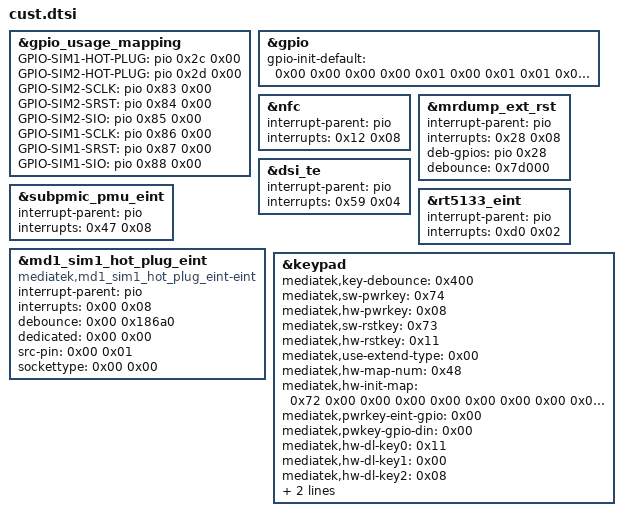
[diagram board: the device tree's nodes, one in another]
// SPDX-License-Identifier: (GPL-2.0 OR MIT)
/*
 * Reconstruction and modifications Copyright (C) 2026 YorokobiMaster (GitHub: @YorokobiMaster)
 *
 * Redmi Turbo 5 Max (dash) customer device-tree data reconstructed from
 * Xiaomi OS3.0.305.0.WPLCNXM stock dtbo.img.
 *
 * This reconstruction does not claim ownership of the original vendor
 * design, interfaces, hardware data, firmware, or other third-party
 * intellectual property. Such rights remain with their respective owners.
 */

&gpio_usage_mapping {
 GPIO-SIM1-HOT-PLUG = <&pio 0x2c 0x00>;
 GPIO-SIM2-HOT-PLUG = <&pio 0x2d 0x00>;
 GPIO-SIM2-SCLK = <&pio 0x83 0x00>;
 GPIO-SIM2-SRST = <&pio 0x84 0x00>;
 GPIO-SIM2-SIO = <&pio 0x85 0x00>;
 GPIO-SIM1-SCLK = <&pio 0x86 0x00>;
 GPIO-SIM1-SRST = <&pio 0x87 0x00>;
 GPIO-SIM1-SIO = <&pio 0x88 0x00>;
};

&gpio {
 gpio-init-default = < 0x00 0x00 0x00 0x00 0x01 0x00 0x01 0x01 0x00 0x01 0x00 0x01 0x00 0x01 0x02 0x00 0x00 0x00 0x01 0x00 0x01 0x03 0x00 0x01 0x00 0x01 0x00 0x01 0x04 0x01 0x00 0x00 0x01 0x00 0x01 0x05 0x00 0x00 0x00 0x01 0x00 0x01 0x06 0x00 0x00 0x00 0x01 0x00 0x01 0x07 0x00 0x00 0x00 0x01 0x01 0x01 0x08 0x00 0x01 0x00 0x01 0x00 0x01 0x09 0x00 0x01 0x01 0x01 0x00 0x01 0x0a 0x00 0x00 0x00 0x01 0x00 0x01 0x0b 0x00 0x00 0x00 0x01 0x00 0x01 0x0c 0x00 0x00 0x00 0x01 0x00 0x01 0x0d 0x00 0x01 0x00 0x01 0x00 0x01 0x0e 0x05 0x00 0x00 0x01 0x00 0x01 0x0f 0x01 0x00 0x00 0x01 0x00 0x01 0x10 0x00 0x00 0x00 0x01 0x00 0x01 0x11 0x00 0x00 0x00 0x01 0x00 0x01 0x12 0x00 0x00 0x00 0x01 0x01 0x01 0x13 0x00 0x01 0x00 0x01 0x00 0x01 0x14 0x00 0x00 0x00 0x01 0x00 0x01 0x15 0x01 0x00 0x00 0x00 0x00 0x01 0x16 0x01 0x00 0x00 0x00 0x00 0x01 0x17 0x01 0x00 0x00 0x00 0x00 0x01 0x18 0x01 0x00 0x00 0x00 0x00 0x01 0x19 0x01 0x00 0x00 0x00 0x00 0x01 0x1a 0x01 0x00 0x00 0x00 0x00 0x01 0x1b 0x00 0x00 0x00 0x01 0x01 0x01 0x1c 0x01 0x00 0x00 0x00 0x00 0x01 0x1d 0x00 0x01 0x01 0x01 0x00 0x01 0x1e 0x00 0x00 0x00 0x01 0x00 0x01 0x1f 0x00 0x00 0x00 0x01 0x00 0x01 0x20 0x07 0x00 0x00 0x01 0x00 0x01 0x21 0x07 0x00 0x00 0x00 0x00 0x01 0x22 0x07 0x00 0x00 0x01 0x00 0x01 0x23 0x07 0x00 0x00 0x00 0x00 0x01 0x24 0x07 0x00 0x00 0x01 0x00 0x01 0x25 0x07 0x00 0x00 0x01 0x00 0x01 0x26 0x07 0x00 0x00 0x01 0x00 0x01 0x27 0x00 0x00 0x00 0x01 0x00 0x01 0x28 0x00 0x00 0x00 0x01 0x01 0x01 0x29 0x00 0x00 0x00 0x01 0x01 0x01 0x2a 0x00 0x00 0x00 0x01 0x00 0x01 0x2b 0x00 0x00 0x00 0x01 0x00 0x01 0x2c 0x01 0x00 0x00 0x01 0x01 0x01 0x2d 0x01 0x00 0x00 0x01 0x01 0x01 0x2e 0x01 0x00 0x00 0x01 0x01 0x01 0x2f 0x01 0x00 0x00 0x01 0x01 0x01 0x30 0x01 0x00 0x00 0x01 0x01 0x01 0x31 0x01 0x00 0x00 0x01 0x01 0x01 0x32 0x01 0x00 0x00 0x01 0x01 0x01 0x33 0x01 0x00 0x00 0x01 0x01 0x01 0x34 0x01 0x00 0x00 0x01 0x01 0x01 0x35 0x01 0x00 0x00 0x01 0x01 0x01 0x36 0x01 0x00 0x00 0x00 0x00 0x01 0x37 0x01 0x00 0x00 0x00 0x00 0x01 0x38 0x01 0x00 0x00 0x00 0x00 0x01 0x39 0x01 0x00 0x00 0x00 0x00 0x01 0x3a 0x01 0x00 0x00 0x01 0x00 0x01 0x3b 0x01 0x00 0x00 0x01 0x00 0x01 0x3c 0x01 0x00 0x00 0x01 0x01 0x01 0x3d 0x01 0x00 0x00 0x00 0x00 0x01 0x3e 0x01 0x00 0x00 0x00 0x00 0x01 0x3f 0x01 0x00 0x00 0x00 0x00 0x01 0x40 0x01 0x00 0x00 0x01 0x01 0x01 0x41 0x00 0x00 0x00 0x01 0x00 0x01 0x42 0x01 0x00 0x00 0x00 0x00 0x01 0x43 0x01 0x00 0x00 0x00 0x00 0x01 0x44 0x01 0x00 0x00 0x00 0x00 0x01 0x45 0x01 0x00 0x00 0x01 0x00 0x01 0x46 0x00 0x00 0x00 0x01 0x00 0x01 0x47 0x00 0x00 0x00 0x01 0x01 0x01 0x48 0x00 0x01 0x01 0x01 0x00 0x01 0x49 0x00 0x00 0x00 0x01 0x00 0x01 0x4a 0x00 0x00 0x00 0x01 0x00 0x01 0x4b 0x01 0x00 0x00 0x00 0x00 0x01 0x4c 0x01 0x00 0x00 0x00 0x00 0x01 0x4d 0x01 0x00 0x00 0x00 0x00 0x01 0x4e 0x01 0x00 0x00 0x00 0x00 0x01 0x4f 0x00 0x00 0x00 0x01 0x00 0x01 0x50 0x00 0x00 0x00 0x01 0x00 0x01 0x51 0x02 0x00 0x00 0x01 0x00 0x01 0x52 0x00 0x01 0x00 0x01 0x00 0x01 0x53 0x02 0x00 0x00 0x01 0x00 0x01 0x54 0x02 0x00 0x00 0x01 0x00 0x01 0x55 0x01 0x00 0x00 0x01 0x00 0x01 0x56 0x01 0x00 0x00 0x01 0x01 0x01 0x57 0x01 0x00 0x00 0x01 0x00 0x01 0x58 0x01 0x00 0x00 0x01 0x00 0x01 0x59 0x01 0x00 0x00 0x01 0x00 0x01 0x5a 0x00 0x01 0x00 0x01 0x00 0x01 0x5b 0x00 0x01 0x00 0x01 0x00 0x01 0x5c 0x00 0x01 0x00 0x01 0x00 0x01 0x5d 0x00 0x01 0x00 0x01 0x00 0x01 0x5e 0x00 0x01 0x00 0x01 0x00 0x01 0x5f 0x02 0x00 0x00 0x00 0x00 0x01 0x60 0x02 0x00 0x00 0x00 0x00 0x01 0x61 0x02 0x00 0x00 0x01 0x00 0x01 0x62 0x02 0x00 0x00 0x00 0x00 0x01 0x63 0x01 0x00 0x00 0x01 0x01 0x01 0x64 0x01 0x00 0x00 0x01 0x01 0x01 0x65 0x01 0x00 0x00 0x01 0x01 0x01 0x66 0x01 0x00 0x00 0x01 0x01 0x01 0x67 0x01 0x00 0x00 0x01 0x00 0x01 0x68 0x01 0x00 0x00 0x01 0x01 0x01 0x69 0x01 0x00 0x00 0x01 0x01 0x01 0x6a 0x00 0x00 0x00 0x00 0x00 0x01 0x6b 0x00 0x01 0x00 0x01 0x00 0x01 0x6c 0x00 0x00 0x00 0x00 0x00 0x01 0x6d 0x00 0x00 0x00 0x00 0x00 0x01 0x6e 0x02 0x00 0x00 0x01 0x00 0x01 0x6f 0x00 0x01 0x00 0x01 0x00 0x01 0x70 0x00 0x01 0x00 0x01 0x00 0x01 0x71 0x00 0x01 0x00 0x01 0x00 0x01 0x72 0x01 0x00 0x00 0x01 0x00 0x01 0x73 0x01 0x00 0x00 0x01 0x01 0x01 0x74 0x01 0x00 0x00 0x01 0x00 0x01 0x75 0x01 0x00 0x00 0x01 0x00 0x01 0x76 0x01 0x00 0x00 0x01 0x00 0x01 0x77 0x01 0x00 0x00 0x01 0x01 0x01 0x78 0x01 0x00 0x00 0x01 0x00 0x01 0x79 0x01 0x00 0x00 0x01 0x01 0x01 0x7b 0x01 0x00 0x00 0x01 0x01 0x01 0x7c 0x01 0x00 0x00 0x01 0x01 0x01 0x7d 0x01 0x00 0x00 0x00 0x00 0x01 0x7e 0x01 0x00 0x00 0x01 0x01 0x01 0x7f 0x01 0x00 0x00 0x01 0x01 0x01 0x80 0x01 0x00 0x00 0x01 0x01 0x01 0x81 0x01 0x00 0x00 0x01 0x01 0x01 0x82 0x01 0x00 0x00 0x01 0x01 0x01 0x83 0x01 0x00 0x00 0x00 0x00 0x01 0x84 0x01 0x00 0x00 0x00 0x00 0x01 0x85 0x01 0x00 0x00 0x01 0x01 0x01 0x86 0x01 0x00 0x00 0x00 0x00 0x01 0x87 0x01 0x00 0x00 0x00 0x00 0x01 0x88 0x01 0x00 0x00 0x01 0x01 0x01 0x89 0x01 0x00 0x00 0x00 0x00 0x00 0x8a 0x01 0x00 0x00 0x01 0x00 0x00 0x8b 0x01 0x00 0x00 0x00 0x00 0x00 0x8c 0x01 0x00 0x00 0x01 0x00 0x00 0x8d 0x01 0x00 0x00 0x00 0x00 0x00 0x8e 0x01 0x00 0x00 0x01 0x00 0x00 0x8f 0x01 0x00 0x00 0x00 0x00 0x00 0x90 0x01 0x00 0x00 0x01 0x00 0x00 0x91 0x01 0x00 0x00 0x00 0x00 0x01 0x92 0x01 0x00 0x00 0x00 0x00 0x01 0x93 0x01 0x00 0x00 0x00 0x00 0x01 0x94 0x01 0x00 0x00 0x00 0x00 0x01 0x95 0x01 0x00 0x00 0x00 0x00 0x01 0x96 0x01 0x00 0x00 0x00 0x00 0x01 0x97 0x01 0x00 0x00 0x00 0x00 0x01 0x98 0x01 0x00 0x00 0x00 0x00 0x01 0x99 0x01 0x00 0x00 0x01 0x00 0x01 0x9a 0x01 0x00 0x00 0x01 0x00 0x01 0x9b 0x01 0x00 0x00 0x01 0x00 0x01 0x9c 0x01 0x00 0x00 0x01 0x00 0x01 0x9d 0x01 0x00 0x00 0x00 0x00 0x01 0x9e 0x01 0x00 0x00 0x00 0x00 0x01 0x9f 0x01 0x00 0x00 0x00 0x00 0x01 0xa0 0x01 0x00 0x00 0x00 0x00 0x01 0xa1 0x01 0x00 0x00 0x01 0x01 0x01 0xa2 0x01 0x00 0x00 0x00 0x00 0x01 0xa3 0x01 0x00 0x00 0x01 0x01 0x01 0xa4 0x01 0x00 0x00 0x01 0x01 0x01 0xa5 0x01 0x00 0x00 0x01 0x01 0x01 0xa6 0x01 0x00 0x00 0x01 0x01 0x01 0xa7 0x01 0x00 0x00 0x01 0x01 0x01 0xa8 0x01 0x00 0x00 0x01 0x00 0x01 0xa9 0x01 0x00 0x00 0x01 0x01 0x01 0xaa 0x01 0x00 0x00 0x01 0x00 0x01 0xab 0x01 0x00 0x00 0x01 0x00 0x01 0xac 0x00 0x00 0x00 0x01 0x01 0x01 0xad 0x00 0x00 0x00 0x01 0x00 0x01 0xae 0x00 0x01 0x00 0x01 0x00 0x01 0xaf 0x00 0x01 0x00 0x01 0x00 0x01 0xb0 0x01 0x00 0x00 0x01 0x01 0x01 0xb1 0x01 0x00 0x00 0x01 0x01 0x01 0xb2 0x07 0x00 0x00 0x01 0x00 0x01 0xb3 0x07 0x00 0x00 0x01 0x00 0x01 0xb4 0x00 0x00 0x00 0x01 0x00 0x01 0xb5 0x00 0x00 0x00 0x01 0x00 0x01 0xb6 0x00 0x00 0x00 0x01 0x00 0x01 0xb7 0x00 0x00 0x00 0x01 0x01 0x01 0xb8 0x00 0x01 0x00 0x01 0x00 0x01 0xb9 0x00 0x01 0x00 0x01 0x00 0x01 0xba 0x00 0x01 0x00 0x01 0x00 0x01 0xbb 0x00 0x01 0x00 0x01 0x00 0x01 0xbc 0x00 0x00 0x00 0x01 0x00 0x01 0xbd 0x00 0x00 0x00 0x01 0x00 0x01 0xbe 0x00 0x00 0x00 0x01 0x00 0x01 0xbf 0x00 0x00 0x00 0x01 0x00 0x01 0xc0 0x01 0x00 0x00 0x01 0x00 0x01 0xc1 0x00 0x01 0x00 0x01 0x00 0x01 0xc2 0x01 0x00 0x00 0x01 0x01 0x01 0xc3 0x01 0x00 0x00 0x01 0x01 0x01 0xc4 0x00 0x00 0x00 0x01 0x00 0x01 0xc5 0x00 0x01 0x00 0x01 0x00 0x01 0xc6 0x01 0x00 0x00 0x01 0x01 0x01 0xc7 0x01 0x00 0x00 0x01 0x01 0x01 0xc8 0x01 0x00 0x00 0x01 0x01 0x01 0xc9 0x01 0x00 0x00 0x01 0x01 0x01 0xca 0x01 0x00 0x00 0x01 0x00 0x01 0xcb 0x01 0x00 0x00 0x01 0x00 0x01 0xcc 0x00 0x01 0x00 0x01 0x00 0x01 0xcd 0x00 0x01 0x00 0x01 0x00 0x01 0xce 0x00 0x01 0x00 0x01 0x00 0x01 0xcf 0x00 0x01 0x00 0x01 0x00 0x01 0xd0 0x00 0x00 0x00 0x01 0x01 0x01 0xd1 0x00 0x01 0x01 0x01 0x00 0x01 0xd2 0x01 0x00 0x00 0x01 0x00 0x01 0xd3 0x00 0x00 0x00 0x01 0x00 0x01 0xd4 0x00 0x01 0x00 0x01 0x00 0x01 0xd5 0x00 0x01 0x00 0x01 0x00 0x01 0xd6 0x01 0x00 0x00 0x01 0x01 0x01 0xd7 0x01 0x00 0x00 0x01 0x01 0x01 0xd8 0x00 0x00 0x00 0x01 0x00 0x01 0xd9 0x01 0x00 0x00 0x01 0x00 0x01 0xda 0x01 0x00 0x00 0x01 0x00 0x01 0xdb 0x07 0x00 0x00 0x01 0x00 0x01 0xdc 0x07 0x00 0x00 0x01 0x00 0x01 0xdd 0x07 0x00 0x00 0x01 0x00 0x01 0xde 0x07 0x00 0x00 0x00 0x00 0x01 0xdf 0x07 0x00 0x00 0x01 0x00 0x01 0xe0 0x00 0x00 0x00 0x01 0x00 0x01 0xe1 0x00 0x00 0x00 0x01 0x00 0x01 0xe2 0x00 0x00 0x00 0x01 0x00 0x01 0xe3 0x00 0x00 0x00 0x01 0x00 0x01 0xe4 0x00 0x00 0x00 0x01 0x00 0x01 0xe5 0x00 0x00 0x00 0x01 0x00 0x01 0xe6 0x00 0x00 0x00 0x01 0x00 0x01 0xe7 0x00 0x00 0x00 0x01 0x00 0x01 0xe8 0x00 0x00 0x00 0x01 0x00 0x01 0xe9 0x00 0x00 0x00 0x01 0x00 0x01 0xea 0x00 0x00 0x00 0x01 0x00 0x01 0xeb 0x00 0x00 0x00 0x01 0x00 0x01 0xec 0x00 0x00 0x00 0x01 0x00 0x01 0xed 0x00 0x00 0x00 0x01 0x00 0x01 0xee 0x00 0x00 0x00 0x01 0x00 0x01 0xef 0x00 0x00 0x00 0x01 0x00 0x01 0xf0 0x00 0x00 0x00 0x01 0x00 0x01 0xf1 0x00 0x00 0x00 0x01 0x00 0x01 0xf2 0x00 0x00 0x00 0x01 0x00 0x01 0xf3 0x00 0x00 0x00 0x01 0x00 0x01 0xf4 0x00 0x00 0x00 0x01 0x00 0x01 0xf5 0x00 0x00 0x00 0x01 0x00 0x01 0xf6 0x00 0x00 0x00 0x01 0x00 0x01 0xf7 0x00 0x00 0x00 0x01 0x00 0x01 0xf8 0x00 0x00 0x00 0x01 0x00 0x01 0xf9 0x00 0x00 0x00 0x01 0x00 0x01 0xfa 0x00 0x00 0x00 0x01 0x00 0x01 0xfb 0x00 0x00 0x00 0x01 0x00 0x01 0xfc 0x00 0x00 0x00 0x01 0x00 0x01 0xfd 0x00 0x00 0x00 0x01 0x00 0x01 0xfe 0x00 0x00 0x00 0x01 0x00 0x00 0xff 0x00 0x00 0x00 0x01 0x00 0x00 0x100 0x00 0x00 0x00 0x01 0x00 0x00 0x101 0x00 0x00 0x00 0x01 0x00 0x00 0x102 0x00 0x00 0x00 0x01 0x00 0x00 0x103 0x00 0x00 0x00 0x01 0x00 0x00 0x104 0x00 0x00 0x00 0x01 0x00 0x00 0x105 0x00 0x00 0x00 0x01 0x00 0x00 0x106 0x00 0x00 0x00 0x01 0x00 0x00 0x107 0x00 0x00 0x00 0x01 0x00 0x00 0x108 0x00 0x00 0x00 0x01 0x00 0x00 0x109 0x00 0x00 0x00 0x01 0x00 0x00 0x10a 0x00 0x00 0x00 0x01 0x00 0x00 0x10b 0x00 0x00 0x00 0x01 0x00 0x00 0x10c 0x00 0x00 0x00 0x01 0x00 0x00 0x10d 0x00 0x00 0x00 0x01 0x00 0x00 0x10e 0x00 0x00 0x00 0x01 0x00 0x00
 >;
};

&nfc {
 interrupt-parent = <&pio>;
 interrupts = <0x12 0x08>;
 status = "okay";
};

&mrdump_ext_rst {
 interrupt-parent = <&pio>;
 interrupts = <0x28 0x08>;
 deb-gpios = <&pio 0x28 0x00>;
 debounce = <0x7d000>;
 status = "okay";
};

&subpmic_pmu_eint {
 interrupt-parent = <&pio>;
 interrupts = <0x47 0x08>;
 status = "okay";
};

&dsi_te {
 interrupt-parent = <&pio>;
 interrupts = <0x59 0x04>;
 status = "okay";
};

&rt5133_eint {
 interrupt-parent = <&pio>;
 interrupts = <0xd0 0x02>;
 status = "okay";
};

&md1_sim1_hot_plug_eint {
 compatible = "mediatek,md1_sim1_hot_plug_eint-eint";
 interrupt-parent = <&pio>;
 interrupts = <0x00 0x08>;
 debounce = <0x00 0x186a0>;
 dedicated = <0x00 0x00>;
 src-pin = <0x00 0x01>;
 sockettype = <0x00 0x00>;
 status = "okay";
};

&keypad {
 mediatek,key-debounce = <0x400>;
 mediatek,sw-pwrkey = <0x74>;
 mediatek,hw-pwrkey = <0x08>;
 mediatek,sw-rstkey = <0x73>;
 mediatek,hw-rstkey = <0x11>;
 mediatek,use-extend-type = <0x00>;
 mediatek,hw-map-num = <0x48>;
 mediatek,hw-init-map = < 0x72 0x00 0x00 0x00 0x00 0x00 0x00 0x00 0x00 0x00 0x00 0x00 0x00 0x00 0x00 0x00 0x00 0x00 0x00 0x00 0x00 0x00 0x00 0x00 0x00 0x00 0x00 0x00 0x00 0x00 0x00 0x00 0x00 0x00 0x00 0x00 0x00 0x00 0x00 0x00 0x00 0x00 0x00 0x00 0x00 0x00 0x00 0x00 0x00 0x00 0x00 0x00 0x00 0x00 0x00 0x00 0x00 0x00 0x00 0x00 0x00 0x00 0x00 0x00 0x00 0x00 0x00 0x00 0x00 0x00 0x00 0x00 >;







 mediatek,pwrkey-eint-gpio = <0x00>;
 mediatek,pwkey-gpio-din = <0x00>;
 mediatek,hw-dl-key0 = <0x11>;
 mediatek,hw-dl-key1 = <0x00>;
 mediatek,hw-dl-key2 = <0x08>;
 mediatek,hw-recovery-key = <0x11>;
 mediatek,hw-factory-key = <0x00>;
 status = "okay";
};
